# lpf5_target_db register map
Vendor: Texas Instruments
Peripheral module from a debugger description file (folder iva2_arp32).
Address unit: 16 bits
Registers are 32-bit, read-write, reset 0x0 unless marked. A register's access mark holds for its fields unless they carry their own. Offsets are as the file gives them; lines under a group give offsets from that group; [hi:lo] are bit positions; {n}, {i} and the like mark numbered series; 'fields as' and 'values as' point back to an identical list; <NAME> marks a mode.

## LPF5 — ipxact12_to_ccs_generated
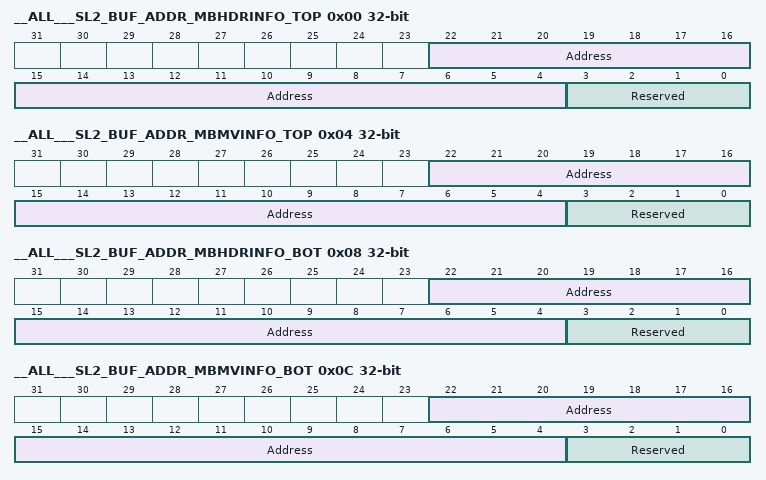
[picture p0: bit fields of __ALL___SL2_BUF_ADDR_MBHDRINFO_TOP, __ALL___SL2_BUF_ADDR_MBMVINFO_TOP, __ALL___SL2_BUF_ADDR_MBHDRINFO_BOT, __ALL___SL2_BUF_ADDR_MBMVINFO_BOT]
0x00 __ALL___SL2_BUF_ADDR_MBHDRINFO_TOP access per field — TOP MBHDRinfo Part1 SL2 Base Address ( Used for Encode Only; Kept for future potential need of reading Mbinfo in Decode)
  [22:4] Address rw
  [3:0] Reserved ro — Lower 4 bits of 128 bit aligned Sl2 Address.
0x04 __ALL___SL2_BUF_ADDR_MBMVINFO_TOP access per field — TOP MBinfo Part2 SL2 Base Address ( Used for Encoder Only; Kept for future potential need of reading Mbinfo in Decode)
  fields as __ALL___SL2_BUF_ADDR_MBHDRINFO_TOP
0x08 __ALL___SL2_BUF_ADDR_MBHDRINFO_BOT access per field — BOT MBinfo Part1 SL2 Base Address (Kept for future potential need of reading Mbinfo in Decode/Encode)
  fields as __ALL___SL2_BUF_ADDR_MBHDRINFO_TOP
0x0C __ALL___SL2_BUF_ADDR_MBMVINFO_BOT access per field — BOT MBinfo Part2 SL2 Base Address (Kept for future potential need of reading Mbinfo in Decode/Encode)
  fields as __ALL___SL2_BUF_ADDR_MBHDRINFO_TOP
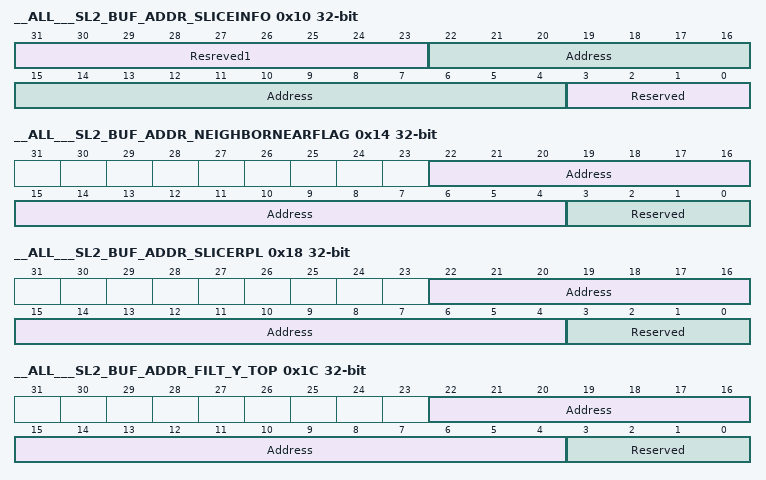
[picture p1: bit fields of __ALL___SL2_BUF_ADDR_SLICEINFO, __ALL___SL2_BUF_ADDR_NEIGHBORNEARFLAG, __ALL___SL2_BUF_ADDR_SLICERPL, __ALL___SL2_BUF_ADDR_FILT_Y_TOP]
0x10 __ALL___SL2_BUF_ADDR_SLICEINFO access per field — SliceInfo Buffer SL2 Base Address
  [31:23] Resreved1 ro
  [22:4] Address rw
  [3:0] Reserved ro — Lower 4 bits of 128 bit aligned Sl2 Address.
0x14 __ALL___SL2_BUF_ADDR_NEIGHBORNEARFLAG access per field — NeighborNear Flag ( BS=1) from ECD Buffer SL2 BA
  fields as __ALL___SL2_BUF_ADDR_MBHDRINFO_TOP
0x18 __ALL___SL2_BUF_ADDR_SLICERPL access per field — RPL Buffer SL2 BA ( Used only in case of Encoder to calculate refpic_id)
  fields as __ALL___SL2_BUF_ADDR_MBHDRINFO_TOP
0x1C __ALL___SL2_BUF_ADDR_FILT_Y_TOP access per field — Even lines of Filtered Luma Tiled-Buffer SL2 Base Addr
  fields as __ALL___SL2_BUF_ADDR_MBHDRINFO_TOP
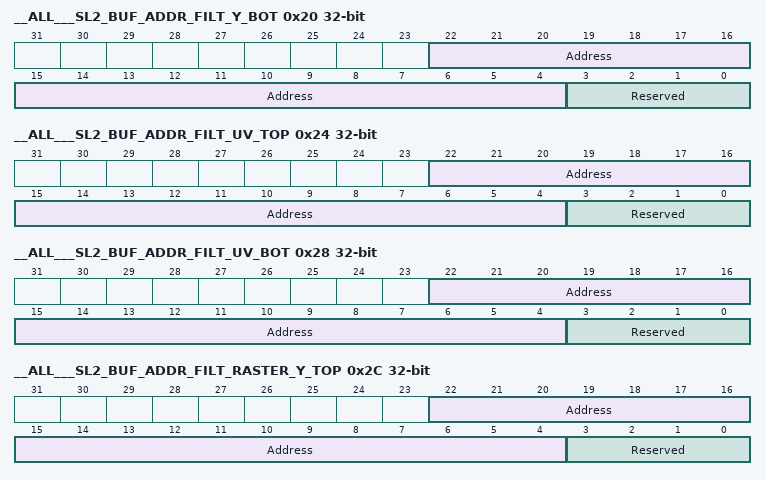
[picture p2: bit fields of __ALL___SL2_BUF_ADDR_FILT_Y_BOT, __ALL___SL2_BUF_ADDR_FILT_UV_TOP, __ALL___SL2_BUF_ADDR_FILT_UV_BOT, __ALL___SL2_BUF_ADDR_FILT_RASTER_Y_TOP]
0x20 __ALL___SL2_BUF_ADDR_FILT_Y_BOT access per field — Odd lines of Filtered Luma Tiled-Buffer SL2 Base Addr
  fields as __ALL___SL2_BUF_ADDR_MBHDRINFO_TOP
0x24 __ALL___SL2_BUF_ADDR_FILT_UV_TOP access per field — Even lines of Filtered Chroma(interleaved NV12) Tiled-Buffer SL2 Base Addr
  fields as __ALL___SL2_BUF_ADDR_MBHDRINFO_TOP
0x28 __ALL___SL2_BUF_ADDR_FILT_UV_BOT access per field — Odd lines of Filtered Chroma(interleaved NV12) Tiled-Buffer SL2 Base Addr
  fields as __ALL___SL2_BUF_ADDR_MBHDRINFO_TOP
0x2C __ALL___SL2_BUF_ADDR_FILT_RASTER_Y_TOP access per field — Even lines of Filtered Luma Raster-Buffer SL2 Base Addr
  fields as __ALL___SL2_BUF_ADDR_MBHDRINFO_TOP
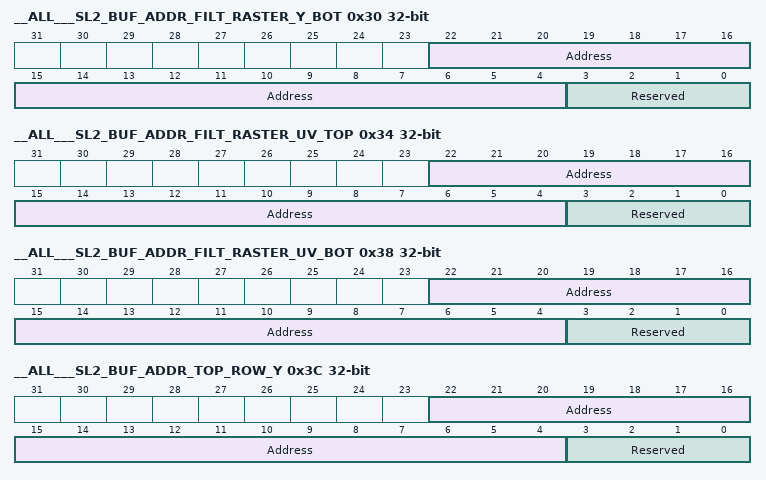
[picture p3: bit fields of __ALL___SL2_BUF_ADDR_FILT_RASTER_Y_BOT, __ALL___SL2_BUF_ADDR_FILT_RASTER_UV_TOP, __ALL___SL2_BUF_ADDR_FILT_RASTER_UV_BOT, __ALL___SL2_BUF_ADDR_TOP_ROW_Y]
0x30 __ALL___SL2_BUF_ADDR_FILT_RASTER_Y_BOT access per field — Odd lines of Filtered Luma Raster-Buffer SL2 Base Addr
  fields as __ALL___SL2_BUF_ADDR_MBHDRINFO_TOP
0x34 __ALL___SL2_BUF_ADDR_FILT_RASTER_UV_TOP access per field — Even lines of Filtered Chroma(interleaved NV12) Raster-Buffer SL2 Base Addr
  fields as __ALL___SL2_BUF_ADDR_MBHDRINFO_TOP
0x38 __ALL___SL2_BUF_ADDR_FILT_RASTER_UV_BOT access per field — Odd lines of Filtered Chroma(interleaved NV12) Raster-Buffer SL2 Base Addr
  fields as __ALL___SL2_BUF_ADDR_MBHDRINFO_TOP
0x3C __ALL___SL2_BUF_ADDR_TOP_ROW_Y access per field — TOP Row of Partially filtered Data Buffer SL2 Base Address. This is same as base adress for Luma. Cb and Cr base adresses are derived out of Luma base address by LPF5.
  fields as __ALL___SL2_BUF_ADDR_MBHDRINFO_TOP
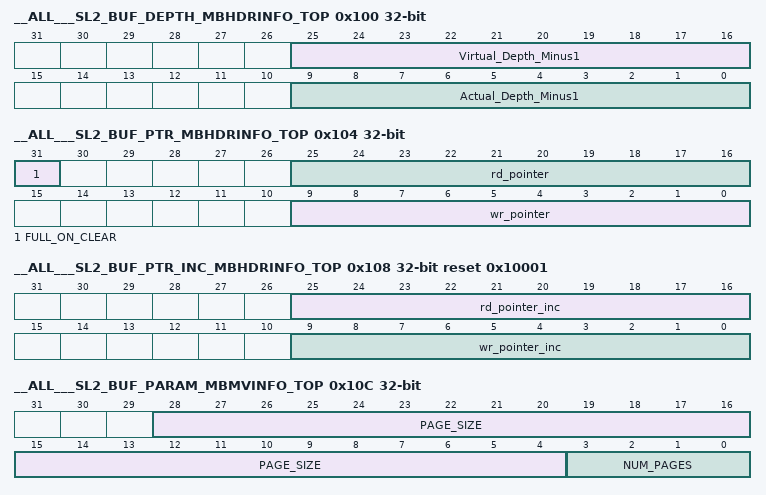
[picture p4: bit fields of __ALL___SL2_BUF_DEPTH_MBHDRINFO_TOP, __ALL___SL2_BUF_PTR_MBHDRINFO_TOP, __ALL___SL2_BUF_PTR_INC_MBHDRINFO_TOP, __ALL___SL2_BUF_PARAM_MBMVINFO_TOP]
0x100 __ALL___SL2_BUF_DEPTH_MBHDRINFO_TOP access per field — EVEN MBINFO Buffer depth configuration register
  [25:16] Virtual_Depth_Minus1 rw, [9:0] Actual_Depth_Minus1 rw
0x104 __ALL___SL2_BUF_PTR_MBHDRINFO_TOP access per field — EVEN MBINFO Buffer Pointer configuration register
  [31] FULL_ON_CLEAR rw
  [25:16] rd_pointer rw — Start value of Read pointer, initialized on BC_CLR. Range: 0 to Actual_buffer_depth_minus1
  [9:0] wr_pointer rw — Start value of Write pointer, initialized on BC_CLR. Range: 0 to Actual_buffer_depth_minus1
0x108 __ALL___SL2_BUF_PTR_INC_MBHDRINFO_TOP access per field reset 0x10001 — Configures the increment offset for buffer pointers of EVENMBInfo
  [25:16] rd_pointer_inc rw — Increment value for read pointer on rd_core_busy deassertion. Range: 0 to Actual_buffer_depth_minus1
  [9:0] wr_pointer_inc rw — Increment value for write pointer on wr_core_busy deassertion. Range: 0 to Actual_buffer_depth_minus1
0x10C __ALL___SL2_BUF_PARAM_MBMVINFO_TOP access per field — MBMVinfo Buffer parameters
  [28:4] PAGE_SIZE rw — Page Size of MBMV info in terms of Byte
  [3:0] NUM_PAGES rw — Number of MVinfo Pages
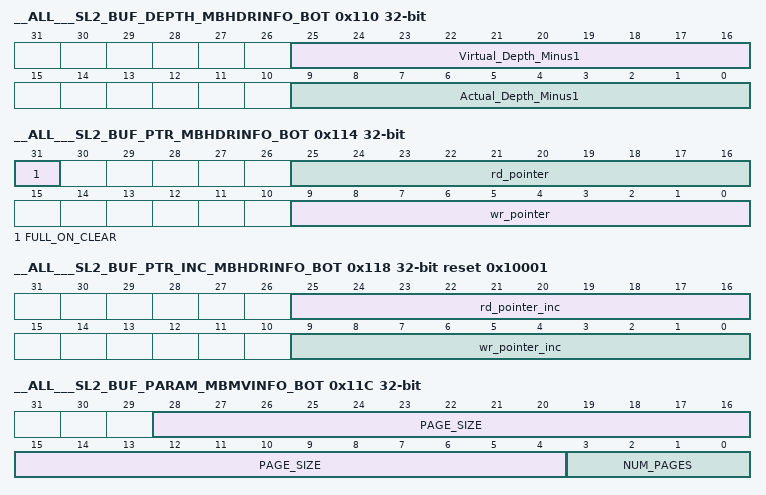
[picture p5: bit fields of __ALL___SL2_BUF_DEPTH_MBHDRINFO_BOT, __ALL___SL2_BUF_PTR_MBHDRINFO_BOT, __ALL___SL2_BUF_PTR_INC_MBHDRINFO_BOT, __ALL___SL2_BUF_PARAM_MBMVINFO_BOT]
0x110 __ALL___SL2_BUF_DEPTH_MBHDRINFO_BOT access per field — ODD MBINFO Buffer depth configuration register
  [25:16] Virtual_Depth_Minus1 rw, [9:0] Actual_Depth_Minus1 rw
0x114 __ALL___SL2_BUF_PTR_MBHDRINFO_BOT access per field — ODD MBINFO Buffer Pointer configuration register
  fields as __ALL___SL2_BUF_PTR_MBHDRINFO_TOP
0x118 __ALL___SL2_BUF_PTR_INC_MBHDRINFO_BOT access per field reset 0x10001 — Configures the increment offset for buffer pointers of ODD MBInfo
  fields as __ALL___SL2_BUF_PTR_INC_MBHDRINFO_TOP
0x11C __ALL___SL2_BUF_PARAM_MBMVINFO_BOT access per field — MBMVinfo Buffer parameters
  fields as __ALL___SL2_BUF_PARAM_MBMVINFO_TOP
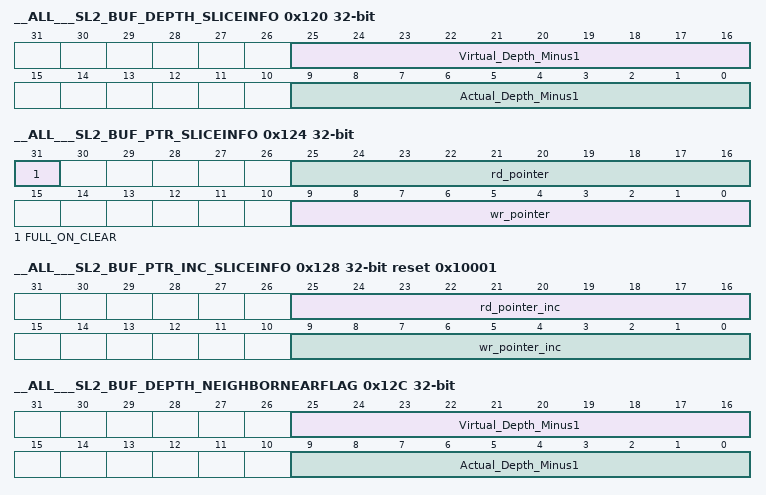
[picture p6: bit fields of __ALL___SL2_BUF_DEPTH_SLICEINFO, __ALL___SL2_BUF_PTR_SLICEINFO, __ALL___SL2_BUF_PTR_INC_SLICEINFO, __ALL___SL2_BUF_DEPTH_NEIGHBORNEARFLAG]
0x120 __ALL___SL2_BUF_DEPTH_SLICEINFO access per field — SliceInfo Buffer depth configuration register
  [25:16] Virtual_Depth_Minus1 rw, [9:0] Actual_Depth_Minus1 rw
0x124 __ALL___SL2_BUF_PTR_SLICEINFO access per field — SliceInfo Buffer Pointer configuration register
  fields as __ALL___SL2_BUF_PTR_MBHDRINFO_TOP
0x128 __ALL___SL2_BUF_PTR_INC_SLICEINFO access per field reset 0x10001 — Configures the increment offset for buffer pointers of SliceInfo
  fields as __ALL___SL2_BUF_PTR_INC_MBHDRINFO_TOP
0x12C __ALL___SL2_BUF_DEPTH_NEIGHBORNEARFLAG access per field — NearFlag Buffer depth configuration register
  [25:16] Virtual_Depth_Minus1 rw, [9:0] Actual_Depth_Minus1 rw
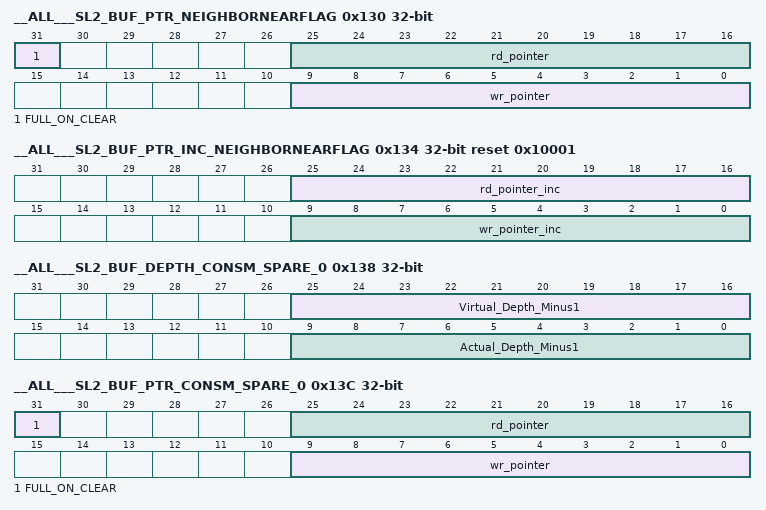
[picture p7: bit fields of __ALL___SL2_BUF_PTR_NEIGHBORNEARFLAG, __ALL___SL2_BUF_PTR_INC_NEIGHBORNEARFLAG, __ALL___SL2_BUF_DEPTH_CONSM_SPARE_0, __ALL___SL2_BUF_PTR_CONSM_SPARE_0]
0x130 __ALL___SL2_BUF_PTR_NEIGHBORNEARFLAG access per field — NeighborNear Flag Buffer Pointer configuration register
  fields as __ALL___SL2_BUF_PTR_MBHDRINFO_TOP
0x134 __ALL___SL2_BUF_PTR_INC_NEIGHBORNEARFLAG access per field reset 0x10001 — Configures the increment offset for buffer pointers of NeighborNear Flag
  fields as __ALL___SL2_BUF_PTR_INC_MBHDRINFO_TOP
0x138 __ALL___SL2_BUF_DEPTH_CONSM_SPARE_0 access per field — CONSM_SPARE_0 Buffer depth configuration register
  [25:16] Virtual_Depth_Minus1 rw, [9:0] Actual_Depth_Minus1 rw
0x13C __ALL___SL2_BUF_PTR_CONSM_SPARE_0 access per field — consumer spare 0 Buffer Pointer configuration register
  fields as __ALL___SL2_BUF_PTR_MBHDRINFO_TOP
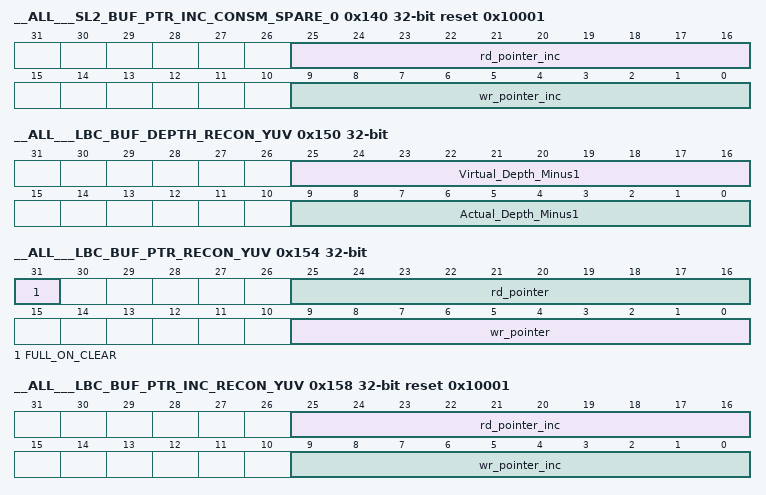
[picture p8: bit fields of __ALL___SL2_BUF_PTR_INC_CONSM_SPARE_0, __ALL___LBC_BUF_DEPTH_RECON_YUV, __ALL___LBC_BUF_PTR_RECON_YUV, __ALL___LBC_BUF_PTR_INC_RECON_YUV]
0x140 __ALL___SL2_BUF_PTR_INC_CONSM_SPARE_0 access per field reset 0x10001 — Configures the increment offset for buffer pointers of consumer spare 0 buffer
  fields as __ALL___SL2_BUF_PTR_INC_MBHDRINFO_TOP
0x150 __ALL___LBC_BUF_DEPTH_RECON_YUV access per field — CALC RECON Buffer depth configuration register
  [25:16] Virtual_Depth_Minus1 rw, [9:0] Actual_Depth_Minus1 rw
0x154 __ALL___LBC_BUF_PTR_RECON_YUV access per field — CALC Recon Buffer Pointer configuration register
  fields as __ALL___SL2_BUF_PTR_MBHDRINFO_TOP
0x158 __ALL___LBC_BUF_PTR_INC_RECON_YUV access per field reset 0x10001 — Configures the increment offset for buffer pointers of CALC DFIFO
  fields as __ALL___SL2_BUF_PTR_INC_MBHDRINFO_TOP
0x160 __ALL___LBC_BUF_BUFFER_ENTRY_SIZE access per field — Number of words in each BUFFER_ENTRY
  [5:0] BUFFER_ENTRY_SIZE_MINUS1 rw — Number of words in each BUFFER_ENTRY = BUFFER_ENTRY_SIZE_MINUS1+1 (4:2:2 --> 1024 Byte / MB of RECON_YUV otherwise 512Byte / MB)
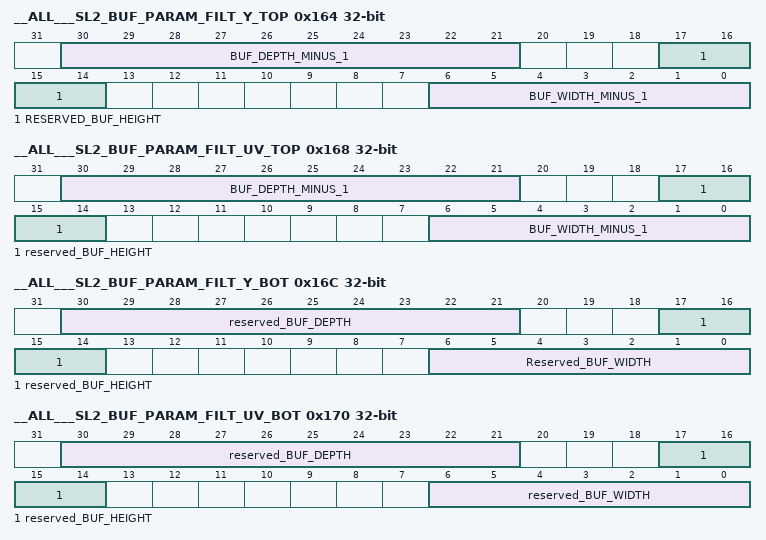
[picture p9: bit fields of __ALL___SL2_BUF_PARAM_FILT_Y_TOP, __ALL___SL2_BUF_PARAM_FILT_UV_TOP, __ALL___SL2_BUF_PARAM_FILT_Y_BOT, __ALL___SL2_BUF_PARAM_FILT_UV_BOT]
0x164 __ALL___SL2_BUF_PARAM_FILT_Y_TOP access per field — Even lines of Filterd Luma Tiled Buffer parameters
  [30:21] BUF_DEPTH_MINUS_1 rw — Number of Filter Buffer as interface between LPF and vDMA. 2 = Ping-pong Filter Buffers ( 2 set of filter buffers) 3 = 3 set of Filter Buffers. 16=16 set of Filter Buffers
  [17:14] RESERVED_BUF_HEIGHT ro — Filter Buffer Height ( Max 20 for H.264) reserved(read 0)
  [6:0] BUF_WIDTH_MINUS_1 rw — Width of Filter-Buffer in terms of 16byte ( Supported N-MB flow is for 1,2,4,8,16 MB )
0x168 __ALL___SL2_BUF_PARAM_FILT_UV_TOP access per field — Even lines of Filterd Chroma Tiled Buffer parameters
  [30:21] BUF_DEPTH_MINUS_1 rw — Number of Filter Buffer as interface between LPF and vDMA. 2 = Ping-pong Filter Buffers ( 2 set of filter buffers) 3 = 3 set of Filter Buffers. 16=16 set of Filter Buffers
  [17:14] reserved_BUF_HEIGHT ro — Filter Buffer Height ( Max 6 for H.264) reserved(read0)
  [6:0] BUF_WIDTH_MINUS_1 rw — Width of Buffer in terms of 16byte ( Supported N-MB flow is for 1,2,4,8,16 MB )
0x16C __ALL___SL2_BUF_PARAM_FILT_Y_BOT ro — Odd lines of Filterd Luma Tiled Buffer parameters
  [30:21] reserved_BUF_DEPTH — Number of Filter Buffer as interface between LPF and vDMA. 2 = Ping-pong Filter Buffers ( 2 set of filter buffers) 3 = 3 set of Filter Buffers. 16=16 set of Filter Buffers
  [17:14] reserved_BUF_HEIGHT — Filter Buffer Height ( Max 20 for H.264)
  [6:0] Reserved_BUF_WIDTH — Width of Buffer in terms of byte ( Supported N-MB flow is for 1,2,4,8,16 MB )
0x170 __ALL___SL2_BUF_PARAM_FILT_UV_BOT ro — Odd lines of Filterd Chroma Tiled Buffer parameters
  [30:21] reserved_BUF_DEPTH — Number of Filter Buffer as interface between LPF and vDMA. 2 = Ping-pong Filter Buffers ( 2 set of filter buffers) 3 = 3 set of Filter Buffers. 16=16 set of Filter Buffers
  [17:14] reserved_BUF_HEIGHT — Filter Buffer Height ( Max 6 for H.264)
  [6:0] reserved_BUF_WIDTH — Width of Buffer in terms of byte ( Supported N-MB flow is for 1,2,4,8,16 MB )
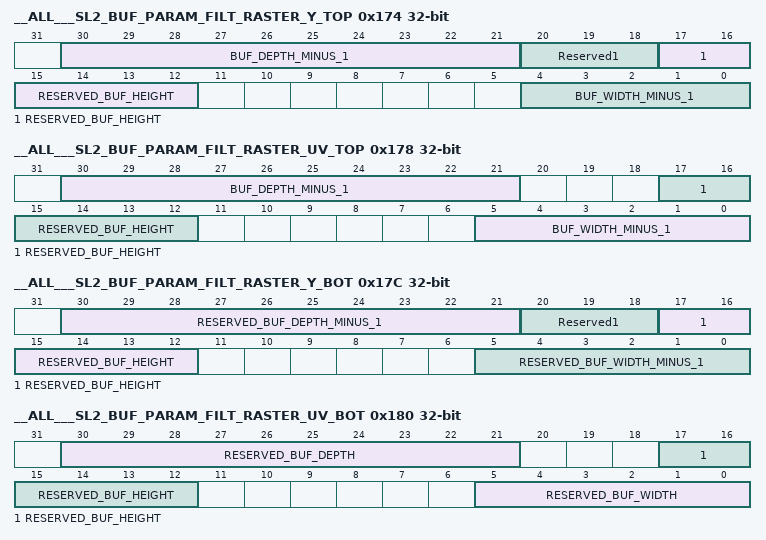
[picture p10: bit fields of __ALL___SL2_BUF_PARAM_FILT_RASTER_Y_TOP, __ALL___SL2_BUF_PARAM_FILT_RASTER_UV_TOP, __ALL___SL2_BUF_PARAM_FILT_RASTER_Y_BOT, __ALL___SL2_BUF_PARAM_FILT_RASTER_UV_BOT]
0x174 __ALL___SL2_BUF_PARAM_FILT_RASTER_Y_TOP access per field — Even lines of Filterd Luma Ratsre Buffer parameters
  [30:21] BUF_DEPTH_MINUS_1 rw — Number of Filter-Buffers as interface between LPF and vDMA. 2 = Ping-pong Filter Buffers ( 2 set of filter buffers) 3 = 3 set of Filter Buffers. 16=16 set of Filter Buffers
  [20:18] Reserved1 ro — 64x64 support
  [17:12] RESERVED_BUF_HEIGHT ro — Height of Filter-Buffer ( Max 20 for H.264 Non-MBAFF; 40 for MBAFF) Reserved (Read 0)
  [4:0] BUF_WIDTH_MINUS_1 rw — Width of 1 entry of Filter-Buffer in terms of 16byte (Supported N-MB flow is for 1,2,4,8,16 MB)
0x178 __ALL___SL2_BUF_PARAM_FILT_RASTER_UV_TOP access per field — Even lines of Filterd Chroma(interleaved,NV12) Raster Buffer parameters
  [30:21] BUF_DEPTH_MINUS_1 rw — Number of Filter Buffer as interface between LPF and vDMA. 2 = Ping-pong Filter Buffers ( 2 set of filter buffers) 3 = 3 set of Filter Buffers. 16=16 set of Filter Buffers
  [17:12] RESERVED_BUF_HEIGHT ro — Filter Buffer Height ( Max 12 for H.264) Reserved(read 0)
  [5:0] BUF_WIDTH_MINUS_1 rw — Width of Buffer in terms of 16byte ( Supported N-MB flow is for 1,2,4,8,16 MB )
0x17C __ALL___SL2_BUF_PARAM_FILT_RASTER_Y_BOT ro — Odd lines of Filterd Luma Ratsre Buffer parameters
  [30:21] RESERVED_BUF_DEPTH_MINUS_1 — Number of Filter-Buffers as interface between LPF and vDMA. 2 = Ping-pong Filter Buffers ( 2 set of filter buffers) 3 = 3 set of Filter Buffers. 16=16 set of Filter Buffers
  [20:18] Reserved1 — 64x64 support
  [17:12] RESERVED_BUF_HEIGHT — Height of Filter-Buffer ( Max 20 for H.264) Reserved (Read 0)
  [5:0] RESERVED_BUF_WIDTH_MINUS_1 — Width of 1 entry of Filter-Buffer in terms of 16byte ( Supported N-MB flow is for 1,2,4,8,16 MB )
0x180 __ALL___SL2_BUF_PARAM_FILT_RASTER_UV_BOT ro — Odd lines of Filterd Chroma(interleaved,NV12) Raster Buffer parameters
  [30:21] RESERVED_BUF_DEPTH — Number of Filter Buffer as interface between LPF and vDMA. 2 = Ping-pong Filter Buffers ( 2 set of filter buffers) 3 = 3 set of Filter Buffers. 16=16 set of Filter Buffers
  [17:12] RESERVED_BUF_HEIGHT — Filter Buffer Height ( Max 12 for H.264)
  [5:0] RESERVED_BUF_WIDTH — Width of Buffer in terms of 16byte ( Supported N-MB flow is for 1,2,4,8,16 MB )
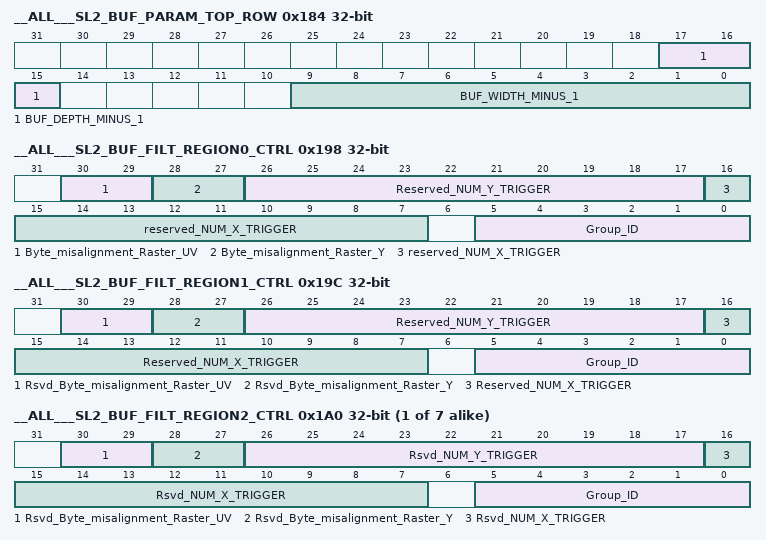
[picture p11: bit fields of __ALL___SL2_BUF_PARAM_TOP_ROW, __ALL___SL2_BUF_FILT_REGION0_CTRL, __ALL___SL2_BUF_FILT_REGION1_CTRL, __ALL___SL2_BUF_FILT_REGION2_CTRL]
0x184 __ALL___SL2_BUF_PARAM_TOP_ROW access per field — TOP ROW Pixels Buffer parameters
  [17:15] BUF_DEPTH_MINUS_1 rw — Configure it to 2 always whenver store into DDR is configured. Configure it to 0 always whenver store into DDR is NOT configured. Kept for future expansion.
  [9:0] BUF_WIDTH_MINUS_1 rw — Buffer Width in terms of 16Bytes. Worst case for 16K frame width with no store into DDR.
0x190 __ALL___SL2_BUF_PARAM_TOP_ROW_STORE_CTRL access per field — Control parameter for top-row buffer Store into DDR
  [5:0] Group_ID rw — Group ID used to trigger vDMA transfer for Store
0x194 __ALL___SL2_BUF_PARAM_TOP_ROW_LOAD_CTRL access per field — Control parameter for top-row buffer load from DDR
  [5:0] Group_ID rw — Group ID used to trigger vDMA transfer for Load
0x198 __ALL___SL2_BUF_FILT_REGION0_CTRL access per field — Region0 Control Parameters
  [30:29] Byte_misalignment_Raster_UV rw — Multiple of 4Byte misalignent in writing Luma data into Filter Buffer for Raster OUT
  [28:27] Byte_misalignment_Raster_Y rw — Multiple of 4Byte misalignent in writing Luma data into Filter Buffer for Raster OUT
  [26:17] Reserved_NUM_Y_TRIGGER ro — Number of Y Trigger used to trigger vDMA transfer for Region#0.
  [16:7] reserved_NUM_X_TRIGGER ro — Number of X Trigger used to trigger vDMA transfer for Region#0.
  [5:0] Group_ID rw — Group ID used to trigger vDMA transfer for Region#0.
0x19C __ALL___SL2_BUF_FILT_REGION1_CTRL access per field — Region1 Control Parameters
  [30:29] Rsvd_Byte_misalignment_Raster_UV ro — Multiple of 4Byte misalignent in writing Luma data into Filter Buffer for Raster OUT
  [28:27] Rsvd_Byte_misalignment_Raster_Y ro — Multiple of 4Byte misalignent in writing Luma data into Filter Buffer for Raster OUT
  [26:17] Reserved_NUM_Y_TRIGGER ro — Number of Y Trigger used to trigger vDMA transfer for Region#1.
  [16:7] Reserved_NUM_X_TRIGGER ro — Number of X Trigger used to trigger vDMA transfer for Region#1.
  [5:0] Group_ID rw — Group ID used to trigger vDMA transfer for Region#1.
{0x198+4i} __ALL___SL2_BUF_FILT_REGION{i}_CTRL access per field (i=2..8) — Region{i} Control Parameters
  [30:29] Rsvd_Byte_misalignment_Raster_UV ro — Multiple of 4Byte misalignent in writing Luma data into Filter Buffer for Raster OUT
  [28:27] Rsvd_Byte_misalignment_Raster_Y ro — Multiple of 4Byte misalignent in writing Luma data into Filter Buffer for Raster OUT
  [26:17] Rsvd_NUM_Y_TRIGGER ro — Number of Y Trigger used to trigger vDMA transfer for Region#{i}.
  [16:7] Rsvd_NUM_X_TRIGGER ro — Number of X Trigger used to trigger vDMA transfer for Region#{i}.
  [5:0] Group_ID rw — Group ID used to trigger vDMA transfer for Region#{i}.
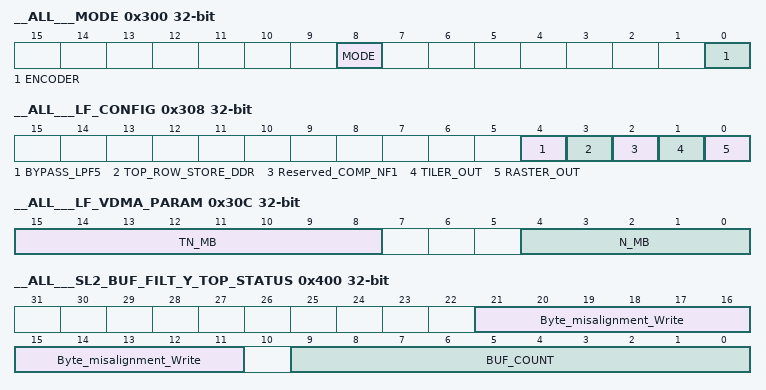
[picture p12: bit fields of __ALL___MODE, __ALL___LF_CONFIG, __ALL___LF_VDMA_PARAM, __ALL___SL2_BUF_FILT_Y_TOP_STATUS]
0x300 __ALL___MODE access per field — LPF Mode register
  [8] MODE rw — 0=>H.241, 1=>Normal
  [0] ENCODER rw — 0=>Decoder, 1=>Encoder
0x304 __ALL___CODEC_TYPE access per field — LPF codec type register
  [3:0] CODEC_TYPE rw — 0=>H.264, 1=>SVC, 2=> reserved
0x308 __ALL___LF_CONFIG access per field — Configuraiton parameter for LPF operation
  [4] BYPASS_LPF5 rw — Bypass LPF5 operations, except loading pixels from REOCN_YUV and storing into SL2. No need to create Left column and create top row or buffer inside SL2. use single descriptor to transfer full RECON_YUV buffer into SL2. ALways use region#4 descriptors.
  [3] TOP_ROW_STORE_DDR rw — TOP row store/load into/from DDR
  [2] Reserved_COMP_NF1 rw — Compute NeighborNear Flag inside ECD5 or LPF5. SW MUST Write '0' into this bit.
  [1] TILER_OUT rw — TILER OUT filter data
  [0] RASTER_OUT rw — RASTER OUT filter data
0x30C __ALL___LF_VDMA_PARAM access per field
  [15:8] TN_MB rw — Value of TN to be used for storing/loading TN_MB partially filtered top-row data through VDMA. Legal Values of TN=16,32,64,128
  [4:0] N_MB rw — Value of N to be used for transferring N-MB filtered data through VDMA. Legal Values of N=1,2,4,8,16 N_MB parameter is fixed for complete frame. It can't change during frame/picture processing.
0x400 __ALL___SL2_BUF_FILT_Y_TOP_STATUS access per field — Buffer Status of Even lines of Luma as Tiled
  [21:11] Byte_misalignment_Write rw
  [9:0] BUF_COUNT rw — Buffer Count within Circular Buffer
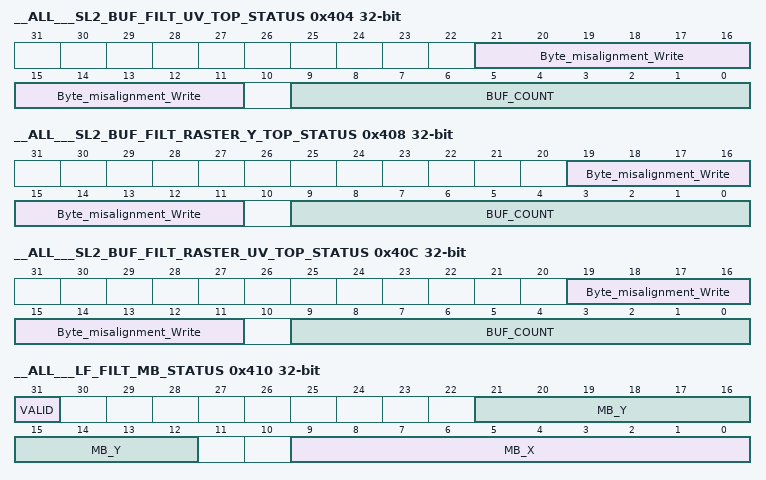
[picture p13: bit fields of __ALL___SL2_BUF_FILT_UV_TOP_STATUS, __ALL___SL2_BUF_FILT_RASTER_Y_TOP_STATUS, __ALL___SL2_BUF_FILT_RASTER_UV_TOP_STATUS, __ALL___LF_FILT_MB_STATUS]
0x404 __ALL___SL2_BUF_FILT_UV_TOP_STATUS access per field — Buffer Status of Even lines of Chroma as Tiled
  [21:11] Byte_misalignment_Write rw — Byte Misalignment from Filter Buffer for current N-MB container.
  [9:0] BUF_COUNT rw — Buffer Count within Circular Buffer
0x408 __ALL___SL2_BUF_FILT_RASTER_Y_TOP_STATUS access per field — Buffer Status of Even lines of Luma as Raster
  [19:11] Byte_misalignment_Write rw — BYte migalignment from Current Filter Buffer start
  [9:0] BUF_COUNT rw — Buffer Count within Filter-Buffer
0x40C __ALL___SL2_BUF_FILT_RASTER_UV_TOP_STATUS access per field — Buffer Status of Even lines of Chroma as Raster
  [19:11] Byte_misalignment_Write rw
  [9:0] BUF_COUNT rw — Buffer Count within Circular Buffer
0x410 __ALL___LF_FILT_MB_STATUS access per field — MB number which is fully filtered into SL2
  [31] VALID rw
  [21:12] MB_Y rw — row number of MB filtered and stored into SL2
  [9:0] MB_X rw — column number of MB filtered and stored into SL2
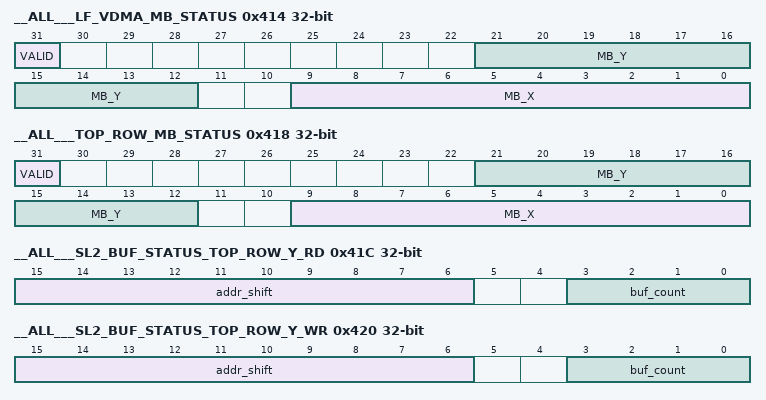
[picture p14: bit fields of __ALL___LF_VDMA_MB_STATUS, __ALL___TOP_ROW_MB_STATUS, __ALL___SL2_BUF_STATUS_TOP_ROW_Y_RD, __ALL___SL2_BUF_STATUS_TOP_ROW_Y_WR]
0x414 __ALL___LF_VDMA_MB_STATUS access per field — MB number which is fully transferrred into DDR
  [31] VALID rw
  [21:12] MB_Y rw — Row number of MB transferred into DDR
  [9:0] MB_X rw — column number of MB transferred into DDR
0x418 __ALL___TOP_ROW_MB_STATUS access per field — MB number whose partially filtered bottom pixels are fully transferred into DDR. This register is also used to track MB number which is fully loaded from DDR. Hence in bottom row of Frame, this register is used to extract loaded MB position, as no store takes place in bottom of frame
  [31] VALID rw
  [21:12] MB_Y rw — row number of MB
  [9:0] MB_X rw — column number of MB. If MB_X >= frame_width in MB, which means end of row has reached.
0x41C __ALL___SL2_BUF_STATUS_TOP_ROW_Y_RD access per field — Operational Read parameters of TOP ROW pixels for Luma
  [15:6] addr_shift rw — address shift from current Buffer for reading next top row 4x4 block
  [3:0] buf_count rw — Buffer count of top-row buffer for Luma Loading
0x420 __ALL___SL2_BUF_STATUS_TOP_ROW_Y_WR access per field — Operational Write parameters of TOP ROW pixels for Luma
  [15:6] addr_shift rw — address shift from current Buffer for storing next top row 4x4 block
  [3:0] buf_count rw — Buffer count of top-row buffer for Luma Storing
0x424 __ALL___SL2_BUF_STATUS_TOP_ROW_U_RD access per field — Operational Read parameters of TOP ROW pixels for Cb
  [15:6] addr_shift rw — address shift from current Buffer for reading next top row 4x4 block
  [3:0] buf_count rw — Buffer count of top-row buffer for Cb Loading
0x428 __ALL___SL2_BUF_STATUS_TOP_ROW_U_WR access per field — Operational Write parameters of TOP ROW pixels for Cb
  [15:6] addr_shift rw — address shift from current Buffer for storing next top row 4x4 block
  [3:0] buf_count rw — Buffer count of top-row buffer for Cb Storing
0x42C __ALL___SL2_BUF_STATUS_TOP_ROW_V_RD access per field — Operational Read parameters of TOP ROW pixels for Cr
  [15:6] addr_shift rw — address shift from current Buffer for reading next top row 4x4 block
  [3:0] buf_count rw — Buffer count of top-row buffer for Cr Loading
0x430 __ALL___SL2_BUF_STATUS_TOP_ROW_V_WR access per field — Operational Write parameters of TOP ROW pixels for Cr
  [15:6] addr_shift rw — address shift from current Buffer for storing next top row 4x4 block
  [3:0] buf_count rw — Buffer count of top-row buffer for Cr Storing
0x434 __ALL___TOP_ROW_STORE_STATUS access per field — Buffer status info for storing into DDR
  [3:0] BUF_COUNT rw — Buffer Count within Circular Buffer
0x438 __ALL___TOP_ROW_LOAD_STATUS access per field — Buffer status info for Loading from DDR
  [3:0] BUF_COUNT rw — Buffer Count within Circular Buffer
0x43C __ALL___SL2_BUF_PTR_VDMA_TRIGGER access per field — VDMA TRIGGer Buffer Pointer configuration register
  [31] FULL_ON_CLEAR rw
  [25:16] rd_pointer rw — Start value of Read pointer, initialized on BC_CLR. Range: 0 to frame_width_in_MB_Minus_1
  [9:0] wr_pointer rw — Start value of Write pointer, initialized on BC_CLR. Range: 0 to frame_width_in_MB_Minus_1
0x440 __ALL___LF_LEFT_TOP_LF_PARAM access per field — Left Top MB Parameters
  [22:16] QP_CR rw
  [15:9] QP_CB rw
  [8:2] QP_Y rw — QP(Luma)
  [1] Frame_MB rw — Frame/Field MB for MBAFF.
  [0] INTRA rw
0x444 __ALL___LF_LEFT_BOT_LF_PARAM access per field — Left Bot MB Parameters
  fields as __ALL___LF_LEFT_TOP_LF_PARAM
0x448 __ALL___LF_LEFT_CBP access per field — Calculated CBP for Left MB/MB-pair ( Saving relevent CBP fileds from current MB/MB-pair for Left MB))
  [19] LEFT_BOT_MB_NEIGHBOR_CBP_3 rw — Neighbor Blockid[15] (MB-pair)
  [18] LEFT_BOT_MB_NEIGHBOR_CBP_2 rw — Neighbor Blockid[13] (MB-Pair)
  [17] LEFT_BOT_MB_NEIGHBOR_CBP_1 rw — Neighbor Blockid[7] (MB-pair)
  [16] LEFT_BOT_MB_NEIGHBOR_CBP_0 rw — Neighbor Blockid[5] of LEFT BOT (MB-pair )
  [3] LEFT_TOP_MB_NEIGHBOR_CBP_3 rw — Neighbor Blockid[15]
  [2] LEFT_TOP_MB_NEIGHBOR_CBP_2 rw — Neighbor Blockid[13]
  [1] LEFT_TOP_MB_NEIGHBOR_CBP_1 rw — Neighbor Blockid[7]
  [0] LEFT_TOP_MB_NEIGHBOR_CBP_0 rw — Neighbor Blockid[5]
0x44C __ALL___LF_CURMB_PROPERTY access per field — Operational property of Current MB/MB-pair.
  [3] MBAFF_TOP_MB rw — indicates top/bot of MBAFF MB-pair.
  [2] FRAME_TOP_ROW rw — indicates whether current MB belongs to top row of Frame.
  [0] SLICE_VALID rw
0x600 __ALL___PID ro reset 0x40000000 — IP Revision Identifier This allows a PID showing X.Y.R in silicon to relate the RTL release with a (close-to-correct) spec version X.Y.S.
  [31:30] scheme — Used to distinguish between old Scheme and current. Spare bit to encode future schemes. Highlander 0.8 value: 0b01
  [27:16] func — Function indicates a software compatible module family. If there is no level of software compatibility a new Func number (and hence PID) should be assigned.
  [15:11] rtl — RTL Version. R as described in PDR with additional clarifications/definitions below. Must be easily ECO-able or controlled during fabrication. Ideally through a top level metal mask or e-fuse. This number is maintained/owned by IP design owner. RTL follows a numbering such as X.Y.R.Z which are explained in this table. R changes ONLY when: (1) PDS uploads occur which may have been due to spec changes (2) Bug fixes occur (3) Resets to '0' when X or Y changes. Design team has an internal 'Z' (customer invisible) number which increments on every drop that happens due to DV and RTL updates. Z resets to 0 when R increments.
  [10:8] major — Major Revision. X as described in PDR with additional clarifications/definitions below. This number is owned/maintained by IP specification owner. X changes ONLY when: (1) There is a major feature addition. An example would be adding Master Mode to Utopia Level2. The Func field (or Class/Type in old PID format) will remain the same. X does NOT change due to: (1) Bug fixes (2) Change in feature parameters.
  [7:6] custom — Indicates a special version for a particular device. Consequence of use may avoid use of standard Chip Support Library (CSL) / Drivers. 0 if non-custom.
  [5:0] minor — Minor Revision. Y as described in PDR with additional clarifications/definitions below. This number is owned/maintained by IP specification owner. Y changes ONLY when: (1) Features are scaled (up or down). Flexibility exists in that this feature scalability may either be represented in the Y change or a specific register in the IP that indicates which features are exactly available. (2) When feature creeps from Is-Not list to Is list. But this may not be the case once it sees silicon; in which case X will change. Y does NOT change due to: (1) Bug fixes (2) Typos or clarifications (3) major functional/feature change/addition/deletion. Instead these changes may be reflected via R, S, X as applicable. Spec owner maintains a customer-invisible number 'S' which changes due to: (1) Typos/clarifications (2) Bug documentation. Note that this bug is not due to a spec change but due to implementation. Nevertheless, the spec tracks the IP bugs. An RTL release (say for silicon PG1.1) that occurs due to bug fix should document the corresponding spec number (X.Y.S) in its release notes.
0x604 __ALL___SYSCONFIG access per field reset 0x8 — Clock management configuration
  [3:2] idlemode rw — Configuration of the local target state management mode. By definition, target can handle read/write transaction as long as it is out of IDLE state.
  [1] AUTOCLOCKGATING_OFF rw — By Default LPF internal sub-modules clocks would be gated based on their activity, for power saving. IF user wishes to run LPF with all its internal clocks are free-running wrt input clock of LPF this bit can be used. 0 = Auto clock gating ON 1 = Auto clock gating OFF
  [0] softreset rw — Software reset. Read 0: Software reset done, no pending action Write 0: No action Write 1: Initiate software reset Read 1: Software reset ongoing Note that great care should be taken when SW user fires SW reset. SW must ensure that all interacting thread with IVAHD level (SL2,AUx-SL2,vDMA groyup one etc ) is idle before issuing SW reset. Otherwise behavior is unpredictable.
0x60C __ALL___IRQ_STATUS_RAW_0 access per field — Per-event raw interrupt status vector, line #0. Raw status is set even if event is not enabled.Write 1 to set the (raw) status, mostly for debug. Write 0: No action Read 0: No event pending Read 1: Event pending Write 1: Set event (debug)
  [8] TOP_ROW_TRANSFER_DONE rw — LPF5 vdma trigger for top-rowbuffer load/store is serviced (group done received).
  [7] FILT_TRANSFER_DONE rw — LPF5 vdma trigger for filtered data transfer is serviced (group done received).
  [6] REWIND_ACK rw — LPF finished pending MB processing including all pending (same stage included) vDMA thread closed , after receiving rewind_pipeline.
  [5] TIMEOUT_ERROR rw — Timeout Error Detected as per LPF_** MMR
  [4] DATA_SYNC rw — settable raw status at DATA SYNC point.
  [3] PIPE_DOWN rw — settable raw status at End of PIPE processing (LPF filter is over and all related vDMA thread is closed)
  [2] END_OF_ROW rw — settable raw status at End of ROW processing ( LPF filtered data for current MB ROW is fully/partially available in SL2; vDMA transfer status NOT known)
  [1] END_OF_SLICE rw — settable raw status at End of Slice processing ( LPF filtered data for current Slice fully/partially available in SL2; vDMA transfer status NOT known)
  [0] END_OF_MB rw — settable raw status at End of MB processing ( LPF filtered data for current MB available in SL2; vDMA transfer status NOT known)
0x610 __ALL___IRQ_STATUS_0 access per field — Per-event "enabled" interrupt status vector, line #0. Enabled status isn't set unless event is enabled. Write 1 to clear the status after interrupt has been serviced (raw status gets cleared, i.e. even if not enabled). Write 0: No action Read 0: No Enabled event pending Read 1: Enabled Event pending Write 1: CLear raw event
  [8] TOP_ROW_TRANSFER_DONE rw — If enabled, LPF5 vdma trigger for top-rowbuffer load/store is serviced (group done received).
  [7] FILT_TRANSFER_DONE rw — If enabled, LPF5 vdma trigger for filtered data transfer is serviced (group done received).
  [6] REWIND_ACK rw — If enabled, LPF finished pending MB processing including all pending (same stage included) vDMA thread closed , after receiving rewind_pipeline.
  [5] TIMEOUT_ERROR rw — Timeout Error if enabled
  [4] DATA_SYNC rw — DATA SYNC point if enabled
  [3] PIPE_DOWN rw — End of PIPE processing if enabled (LPF filter is over and all related vDMA thread is closed)
  [2] END_OF_ROW rw — End of ROW processing if enabled ( LPF filtered data for current MB ROW is fully/partially available in SL2; vDMA transfer status NOT known)
  [1] END_OF_SLICE rw — End of Slice processing if enabled ( LPF filtered data for current Slice fully/partially available in SL2; vDMA transfer status NOT known)
  [0] END_OF_MB rw — settable status at End of MB processing ( LPF filtered data for current MB available in SL2; vDMA transfer status NOT known)
0x614 __ALL___IRQ_ENABLE_SET_0 access per field — Per-event interrupt enable bit vector, line #0. Write 1 to set (enable interrupt). Readout equal to corresponding _CLR register. Write 0: No action Read 0: Interrupt disabled (masked) Read 1: Interrupt enabled Write 1: Enable interrupt
  [8] TOP_ROW_TRANSFER_DONE rw — Enable for TOP_ROW_TRANSFER_DONE
  [7] FILT_TRANSFER_DONE rw — Enable for FILT_TRANSFER_DONE
  [6] REWIND_ACK rw — Enable for REWIND_ACK
  [5] TIMEOUT_ERROR rw — Enable for TIMEOUT_ERROR
  [4] DATA_SYNC rw — Enable for DATA_SYNC
  [3] PIPE_DOWN rw — Enable for PIPE_DOWN
  [2] END_OF_ROW rw — Enable for END_OF_ROW
  [1] END_OF_SLICE rw — Enable for END_OF_SLICE
  [0] END_OF_MB rw — enable for END_OF_MB
0x618 __ALL___IRQ_ENABLE_CLR_0 access per field — Per-event interrupt enable bit vector, line #0. Write 1 to clear (disable interrupt). Readout equal to corresponding _SET register. Write 0: No action Read 0: Interrupt disabled (masked) Read 1: Interrupt enabled Write 1: Disable interrupt
  fields as __ALL___IRQ_ENABLE_SET_0
0x61C __ALL___IRQ_BLOCKING_CFG_0 access per field — Interrupt blocking configuration for interrupt line - 0
  [8] TOP_ROW_TRANSFER_DONE rw — Blocking configuration for interrupt source_0 1: interrupt source is blocking type 0: interrupt source is non-blocking type. The configuration in this register only apply to enabled interrupt sources
  [7] FILT_TRANSFER_DONE rw — Blocking configuration for interrupt source_0 1: interrupt source is blocking type 0: interrupt source is non-blocking type. The configuration in this register only apply to enabled interrupt sources
  [6] REWIND_ACK rw — Blocking configuration for interrupt source_0 1: interrupt source is blocking type 0: interrupt source is non-blocking type. The configuration in this register only apply to enabled interrupt sources
  [5] TIMEOUT_ERROR rw — Blocking configuration for interrupt source_0 1: interrupt source is blocking type 0: interrupt source is non-blocking type. The configuration in this register only apply to enabled interrupt sources
  [4] DATA_SYNC rw — Blocking configuration for interrupt source_0 1: interrupt source is blocking type 0: interrupt source is non-blocking type. The configuration in this register only apply to enabled interrupt sources
  [3] PIPE_DOWN rw — Blocking configuration for interrupt source_0 1: interrupt source is blocking type 0: interrupt source is non-blocking type. The configuration in this register only apply to enabled interrupt sources
  [2] END_OF_ROW rw — Blocking configuration for interrupt source_0 1: interrupt source is blocking type 0: interrupt source is non-blocking type. The configuration in this register only apply to enabled interrupt sources
  [1] END_OF_SLICE rw — Blocking configuration for interrupt source_0 1: interrupt source is blocking type 0: interrupt source is non-blocking type. The configuration in this register only apply to enabled interrupt sources
  [0] END_OF_MB rw — Blocking configuration for interrupt source_0 1: interrupt source is blocking type 0: interrupt source is non-blocking type. The configuration in this register only apply to enabled interrupt sources
0x640 __ALL___LF_ENABLE access per field — LPF5 Enable Register
  [0] ENABLE rw
0x644 __ALL___PROGRAM_AUTO_LOAD access per field — Enable and SL2 location of the Auto Load MMR Image
  [31] AUTO_PROGRAM_LOAD_EN rw — Auto Load Enabled 1 => Program Auto Load Enabled
  [22:4] AUTO_PROGRAM_ADDR rw — Program Auto Load SL2 Base Address
0x64C __ALL___LF_DATA_SYNC access per field — Number of rows to generate interrupt after finishing filter and complete transfer of filtered data of N Rows in DDR( Taske care of vDMA thread)
  [8:0] NUM_ROWS rw — Starting with Row No = 0 till Row No= 511(for 8K); Interrupt would be generated after filterring and completing vDMA transfer of all MB of number of rows configured here from previous interrupt generation. i.e. interrupt would be generated after row_number NUM_ROWS, 2*NUM_ROWS, 3*NUM_ROWS and continues..
0x650 __ALL___LF_BC_CLR access per field — SYNCBOX5 register Initializes the BC pointers to the configured values (as configured in the BC_PTR MMR). Single BC_CLR register in HWA with a CLEAR bit per buffer. CLEAR bits should exist for both output & input buffers. BC_CLR should be set only when the BC is in IDLE State and all the other BC registers are programmed to avoid the undefined behaviour. Software needs to ensure that BC_CLR write is non-posted.
  [6] LF_VDMA_TRIGGER wo — Internal SL2BC for vDMA trigger management.
  [5] LBC_BUF_RECON_YUV_CLEAR wo
  [4] SL2_BUF_CONSM_SPARE_0_CLEAR wo
  [3] SL2_BUF_NEIGHBORNEARFLAG_CLEAR wo
  [2] SL2_BUF_SLICEINFO_CLEAR wo
  [1] SL2_BUF_MBHDRINFO_BOT_CLEAR wo
  [0] SL2_BUF_MBHDRINFO_TOP_CLEAR wo
0x654 __ALL___LF_CORE_TIMEOUT access per field reset 0xFA0 — Timeout Error detection
  [12:1] CYCLE_COUNT rw — Cycle count for Time out detection.
  [0] EN rw — Enabling timeout feature
0x658 __ALL___LF_VDMA_TIMEOUT access per field reset 0xFA0 — Timeout Error detection
  fields as __ALL___LF_CORE_TIMEOUT
0x65C __ALL___BC_ENABLE access per field — Enable MMR for BCs in LPF5. If register bit is 0, the corresponding BC's ready is not looked for thread to proceed its execution. '1' = Enable BC Ready '0' = Disable BC ready
  [9] BC_EN_VDMA_TOP_ROW_LOAD_TRIGGER rw — Enabling BC Readys
  [8] BC_EN_VDMA_TOP_ROW_STORE_TRIGGER rw — Enabling BC Readys
  [7] BC_EN_VDMA_FILT_TRIGGER rw — Enabling BC Readys
  [6] BC_EN_RECON_YUV rw — Enabling BC Readys
  [5] BC_EN_PROD_SPARE_0 rw — Enabling BC Readys
  [4] BC_EN_CONSM_SPARE_0 rw — Enabling BC Readys
  [3] BC_EN_NEIGHBORNEARFLAG rw — Enabling BC Readys
  [2] BC_EN_SLICEINFO rw — Enabling BC Readys
  [1] BC_EN_MBHDRINFO_BOT rw — Enabling BC Readys
  [0] BC_EN_MBHDRINFO_TOP rw — Enabling BC Readys
0x660 __ALL___LF_BC_GLUE_CLR access per field — Always write '0' into this register.
  [9] LF_VDMA_TOP_ROW_LOAD_GLUE_CLR rw, [8] LF_VDMA_TOP_ROW_STORE_GLUE_CLR rw, [7] LF_VDMA_FILT_TRIGGER_GLUE_CLR wo, [6] LBC_BUF_RECON_YUV_GLUE_CLR wo, [5] SL2_BUF_PROD_SPARE_0_GLUE_CLR wo, [4] SL2_BUF_CONSM_SPARE_0_GLUE_CLR wo, [3] SL2_BUF_NEIGHBORNEARFLAG_GLUE_CLR wo, [2] SL2_BUF_SLICEINFO_GLUE_CLR wo, [1] SL2_BUF_MBHDRINFO_BOT_GLUE_CLR wo, [0] SL2_BUF_MBHDRINFO_TOP_GLUE_CLR wo
0x664 __ALL___BC_IDLE access per field — Disables the bc_ready generation. Bc_pointer is untouched
  [8] LF_VDMA_TOP_ROW_LOAD_IDLE wo — Internal custom fifo to handle top-row trigger generation for load. Don't use this bit.
  [7] LF_VDMA_TOP_ROW_STORE_IDLE wo — Internal custom fifo to handle top-row trigger generation for store. Load Buffer interface is handled through this bit only. Back up bit for future.
  [6] LF_VDMA_TRIGGER_IDLE wo — Internal SL2BC for vDMA trigger management.
  [5] LBC_BUF_RECON_YUV_IDLE wo
  [4] SL2_BUF_CONSM_SPARE_0_IDLE wo
  [3] SL2_BUF_NEIGHBORNEARFLAG_IDLE wo
  [2] SL2_BUF_SLICEINFO_IDLE wo
  [1] SL2_BUF_MBHDRINFO_BOT_IDLE wo
  [0] SL2_BUF_MBHDRINFO_TOP_IDLE wo
0x700 __ALL___DBG_CAP ro reset 0x500000 — This register contains the node revision code (all syncbox types) and all debug capacities of the module for HWa based syncbox only
  [26] DBG_SWBP_SUP — Whether HWA Core supports SWBP or not. b0 – Not Supported b1 – Supported
  [25] DBQ_RESET_SUP — Whether HWA Core reset is supported or not which does not affect debug logic. b0 – Not Supported b1 – Supported
  [24] SYS_EXE_REQ — Whether HWA Core Execution status and control is supported. b0 – Not Supported b1 – Supported
  [23] TRIG_OUTPUT — b0 – Trigger Outputs are not supported b1 - Trigger Outputs are supported
  [22] TRIG_INPUT — b0 - Trigger Inputs are not supported b1 - Trigger Inputs are supported
  [21:20] TRIG_CHNS — Number of Trigger Channels Supported b00 ------ No channels supported b01 ------ One channel supported b10 ------ Two channels supported Others ---- Reserved
  [19:16] NUM_CNTS — The number of counter modules that exist. The registers supporting the counter modules must be implemented consecutively in the memory map
  [15:12] NUM_WPS — The number of watchpoint modules that exist. The registers supporting the watchpoint modules must be implemented consecutively in the memory map
  [11:8] NUM_BPS — The number of breakpoint modules that exist. The registers supporting the breakpoint modules must be implemented consecutively in the memory map
0x704 __ALL___DBG_CNTL access per field
  [19:16] DBG_EMU0_CNTL ro — EMU0 output control. The cross trigger output control. This values in this field determine the behavior of the outputs generated on EMU0. NOTE: The effect of setting ‘1’ is ignored if the HWA Core is currently in HALTED state until the HWA core exits and re-enters HALTED state. DBG_EMUn_CNTL Output Enable Output Pulse Description 0 De-asserted 0 NA No output. Input only 1 Stopping 0 Yes Pulse on halt. If this bit is set when halted then no effect until the HWA re-enters halted state. 2 HWBP 0 Yes Pulse when any HWBP triggers 3 HWWP 0 Yes Pulse when any HWWP triggers 4 Asserted 1 No Drive pin high 5 Asserted 0 No Drive pin low 6-15 - - Reserved
  [14] DBG_STAT_EMU0 ro — Statues of EMU0 input. This bit indicates the current value of the EMU0 input
  [12] DBG_HALT_EMU0 ro — Execution halted due to trigger in on EMU0 input • Set to ‘1’ when halt due to EMU0 input completes • Set to ‘0’ when execution resumes
  [11] DBG_HALT_USER ro — Execution halted due to register update of DBG_HALT • Set to ‘1’ when halt due to DBG_HALT update completes • Set to ‘0’ when execution resumes
  [10] DBG_HALT_STEP ro — Execution halted due to single step completion • Set to ‘1’ when the single step completes • Set to ‘0’ when execution resumes
  [9] DBG_HALT_BPWP ro — Execution halted due to trigger from HWBP or WP. • Set to ‘1’ halt due to breakpoint or watchpoint completes • Set to ‘0’ when execution resumes
  [7] DBG_EXE_STAT ro — The execution status of the module • Set to ‘1’ when halted due to debug event • Set to ‘0’ when execution resumes
  [5] DBG_EMU0_EN rw — EMU0 input trigger enable • Writing ‘1’ enables halting on the falling edge of the EMU0 input • Writing ‘0’ disables halts via EMU0 input
  [4] DBG_WPBP_EN rw — This bit enables the halts on watchpoint or hardware breakpoint trigger events. • Writing ‘1’ enables halting on any hardware breakpoint or watchpoint trigger  Each breakpoint or watchpoint resource also has a local enable • Writing ‘0’ disables halts via hardware breakpoints or watchpoints
  [2] DBG_SINGLE_STEP_EN rw — Single Step Execution enable. When this bit is set, the accelerator core shall be halted upon execution of a single instruction. This is after the accelerator core has left the halted state by clearing the DBG_HALT control bit. • Writing ‘1’ enables halting when the next instruction following exit from halted state is executed. • Writing ‘0’ disables halts via single step. NOTE: 1. When the accelerator core enters its natural execution state, it may or may not execute an instruction and re-enter HALTED state.
  [1] DBG_RESTART rw — Debug Restart Status bit. This bit is normally set when the DBG_HALT bit transitions from ‘1’ to ‘0’ when the natural execution state is entered. It is a sticky bit. It may also be set when a synchronous run causes the accelerator to leave halted state. • Reading ‘1’ means HWA Core exited halted state (at least temporarily). • Reading ‘0’ means HWA Core did not exit halted state. • Writing ‘1’ shall clear the bit if set. There is no restriction on when it can be cleared. • Writing ‘0’ shall have no effect.
  [0] DBG_HALT rw — Global debug run control The bit will be read as being set upon entry to HALTED state due to halted state being entered because of SWBP, HWBP, HWWP, EMU0 / 1 trigger or manual halt requested through this control. • Writing ‘1’ when read ‘0’ shall cause a halt on the next possible halt boundary. • Writing ‘0’ when read ‘1’ returns the system to the natural execution state. A synchronous run hardware request has the same effect. • Reading ‘1’ means that the halted state has been reached or been requested by the manual halt mechanism • Reading ‘0’ means that the target is in its natural execution state. NOTE: 1. The natural execution state means the FSM state entered prior to last entry into Halted state. 2. This would be the last application requested FSM state unless the DBG_SYS_EXE_REQ control was used to change it.
0x708 __ALL___DBG_HWBP_0_CNTL access per field — Hardware Brakepoint-0 Control (at MB-Index) (LPF Execute Thread)
  [2] TRIGGERED rw — This bit is Set to "1" when HWBP located at the MB_Index in DBG_HWBP_n_MB_Index is executed Set to ‘1’ when executing the MB index = DBG_HWBP_n_MB_Index Cleared to ‘0’ by writing ‘1’ to this bit
  [1] HALT rw — This bit configures the module to generate halt when triggered Writing ‘1’ enables a HWA halt when triggered. The DBG_CNTL:DBG_HALT_BPWP must also be set for the halt to occur Writing ‘0’ disables halt upon trigger
  [0] ENBALE rw — This is the local enable for the hardware breakpoint module Writing ‘1’ to this bit enables the module to generate an instruction address match trigger Writing ‘0’ to this bit disables the module
0x70C __ALL___DBG_HWBP_0_MB_Index access per field — Hardware Brakepoint-0 : At MB-Index (LPF Execute Thread)
  [24:16] Column_Index rw, [8:0] Row_Index rw
0x710 __ALL___DBG_HWBP_1_CNTL access per field — Hardware Brakepoint-0 Control (at MB-Index) (LPF-vDMA Thread)
  fields as __ALL___DBG_HWBP_0_CNTL
0x714 __ALL___DBG_HWBP_1_MB_Index access per field — Hardware Brakepoint-0 : At MB-Index (LPF-vDMA Thread)
  [24:16] Column_Index rw, [8:0] Row_Index rw
0x730 __ALL___LF_DEBUG0 access per field
  [2] BYPASS_NF1_LOAD rw — Bypass NF1 loading from SL2 '1' = don't load NF1 from SL2, instead use programmed value '0' = NOrmal functional behavior
  [1] BYPASS_FILTER rw — Bypass Filter operation. CompBS, Loading of Param, Loading of Data and Storing of data happens as usual. ONLY filter engine is switched of.
  [0] BYPASS_CompBS rw — Bypass comp BS function
0x740 __ALL___DESIGN_RESERVED access per field — SW MUST Write 0 into all of its bits NO Coverage required for contents of this register. Primary usecase is to implement some controlled feature in future after MMR freeze.
  [n] FEATURE{n}_RESERVED rw (n=0..7)
0x780 __ALL___SL2_BUF_STATUS_MBHDRINFO_TOP ro reset 0x80000000 — Refer to SYNCBOX-5 functional specification
  [31] EMPTY, [27:26] READ_STATUS, [25:16] RD_POINTER, [15] full, [11:10] WR_STATUS, [9:0] WR_POINTER
0x784 __ALL___SL2_BUF_STATUS_MBHDRINFO_BOT ro reset 0x80000000 — Refer to SYNCBOX-5 functional specification
  fields as __ALL___SL2_BUF_STATUS_MBHDRINFO_TOP
0x788 __ALL___SL2_BUF_STATUS_SLICEINFO ro reset 0x80000000 — Refer to SYNCBOX-5 functional specification
  fields as __ALL___SL2_BUF_STATUS_MBHDRINFO_TOP
0x78C __ALL___SL2_BUF_STATUS_NEIGHBORNEARFLAG ro reset 0x80000000 — Refer to SYNCBOX-5 functional specification
  fields as __ALL___SL2_BUF_STATUS_MBHDRINFO_TOP
0x790 __ALL___SL2_BUF_STATUS_CONSM_SPARE_0 ro reset 0x80000000 — Refer to SYNCBOX-5 functional specification
  fields as __ALL___SL2_BUF_STATUS_MBHDRINFO_TOP
0x798 __ALL___LBC_BUF_STATUS_RECON_YUV ro reset 0x80000000 — Refer to SYNCBOX-5 functional specification
  fields as __ALL___SL2_BUF_STATUS_MBHDRINFO_TOP
0x79C __ALL___SL2_BUF_STATUS_VDMA_TRIGGER ro reset 0x80000000 — Refer to SYNCBOX-5 functional specification
  fields as __ALL___SL2_BUF_STATUS_MBHDRINFO_TOP
{0x800+4i} __ALL___LF_CUR_MB_INFO_{i} ro (i=0..3)
  [31:0] CUR_MB_INFO_{i} — CUR MBInfo[{32i+31}:{32i}]
{0x810+4i} __ALL___LF_SLICE_INFO_{i} ro (i=0..3)
  [31:0] SLICEINFO_WORD{i} — SliceInfo[{32i+31}:{32i}]
0x820 __ALL___LF_CUR_CBP ro — Calculated CBP for Current MB/MB-pair ( Using RSD_VALID from CALC ; details refer to LPF spec)
  [31:16] CBP_COMP_MB — CBP of complementry MB( MB-pair) [15:0]
  [15:0] CBP_CUR_MB — CBP[15:0]
0x824 __ALL___LF_MBAFF_COMP_MB_LF_PARAM ro — MBAFF Complimentary MB parameters. For current=TOP MB, this register is useless. For current=BOT MB of MBAFF, this register contains parameters of TOP MB of MBAFF-pair.
  [22:16] QP_CR
  [15:9] QP_CB
  [8:2] QP_Y — QP(Luma)
  [1] Frame_MB — Frame/Field MB for MBAFF.
  [0] INTRA
0x828 __ALL___LF_UPPER_TOP_LF_PARAM ro — Upper TOP MB Parameters (Only MBAFF)
  fields as __ALL___LF_MBAFF_COMP_MB_LF_PARAM
0x82C __ALL___LF_UPPER_BOT_LF_PARAM ro — Upper BOT MB Parameters (MBAFF) Upper MB for Non-MBAFF
  fields as __ALL___LF_MBAFF_COMP_MB_LF_PARAM
0x830 __ALL___LF_UPPER_CBP ro — Calculated CBP for Upper MB/MB-pair
  [23] UPPER_BOT_FRAMEPAIR_NEIGHBOR_CBP_3 — Neighbor Blockid[13] (Only MBAFF+Frame-pair)
  [22] UPPER_BOT_FRAMEPAIR_NEIGHBOR_CBP_2 — Neighbor Blockid[12] (Only MBAFF+Frame-pair)
  [21] UPPER_BOT_FRAMEPAIR_NEIGHBOR_CBP_1 — Neighbor Blockid[9] (Only MBAFF+Frame-pair)
  [20] UPPER_BOT_FRAMEPAIR_NEIGHBOR_CBP_0 — Neighbor Blockid[8] (Only MBAFF+Frame-pair)
  [19] UPPER_BOT_MB_NEIGHBOR_CBP_3 — Neighbor Blockid[15]
  [18] UPPER_BOT_MB_NEIGHBOR_CBP_2 — Neighbor Blockid[14]
  [17] UPPER_BOT_MB_NEIGHBOR_CBP_1 — Neighbor Blockid[11]
  [16] UPPER_BOT_MB_NEIGHBOR_CBP_0 — Neighbor Blockid[10]
  [3] UPPER_TOP_MB_NEIGHBOR_CBP_3 — Neighbor Blockid[15]
  [2] UPPER_TOP_MB_NEIGHBOR_CBP_2 — Neighbor Blockid[14]
  [1] UPPER_TOP_MB_NEIGHBOR_CBP_1 — Neighbor Blockid[11]
  [0] UPPER_TOP_MB_NEIGHBOR_CBP_0 — Neighbor Blockid[10]
0x83C __ALL___LF_NEIGHBOR_MB access per field — Neighbor MB number created during compBS to be used for averaging Qp values. neighbor_mb contains neibhbor MB number for All 8 pixels on Left MB Edge and one MB number for horizontal Mb Edge.
  [26:0] Neighbor_mb rw — [11:0] = MB_number for bs_edges [3,2,1,0] (Vertical MB edge) [23:12] = MB_number for bs_edges [35,34,33,32] (Vertical MB edge) [26:24] = MB_number for bs_edges [22] ( Horizontal MB edge)
0x840 __ALL___LF_NF — Neighbor Near Flag Value
  [31:0] NeighborNear_Flag — Neighbor Near flag bit0=edge0 bit31=edge31 as per NeighborNear Flag indexing as specified in spec. Value dumped by ECD5 into SL2 and loaded from SL2.
0x844 __ALL___LF_BS_0 access per field — Boundary Strength Value
  [3n+2:3n] BS_EDGE_{n} rw (n=0..9) — BS value
0x848 __ALL___LF_BS_1 access per field — Boundary Strength Value
  [3n-28:3n-30] BS_EDGE_{n} rw (n=11..19) — BS value
  [2:0] BS_EDGE_10 rw — BS value 1 msb of 3 bit of BS_EDGE_10
0x84C __ALL___LF_BS_2 access per field — Boundary Strength Value
  [3n-58:3n-60] BS_EDGE_{n} rw (n=22..29)
  [5:3] BS_EDGE_21 rw — BS value 2 msb of 3 bit of BS_EDGE_21
  [2:0] BS_EDGE_20 rw
0x850 __ALL___LF_BS_3 access per field — Boundary Strength Value for some extra edges in case of MBAFF MB boundary.
  [3n-88:3n-90] BS_EDGE_{n} rw (n=30..39) — BS value
0x854 __ALL___LF_STATUS_0 ro — All internal state machine status
  [31:0] LPF_INTERNAL_STATUS
0x858 __ALL___LF_VDMA_FILT_STATUS ro — filter buffer VDMA transfer status
  [5:2] TRIG_REGION — Triggered Region
  [1] VDMA_TRANSFER_STATUS
  [0] VDMA_TRIGGER_STATUS
0x85C __ALL___LF_VDMA_TOP_ROW_STATUS ro — top-row buffer VDMA transfer status
  fields as __ALL___LF_VDMA_FILT_STATUS
{0x860+4i} __ALL___HWA_THREAD_STATUS_{i} ro (i=0..2) — Thread[{i}] Status
  [6] HALT_DEBUG_OUT — Halted because of debug out request
  [5] HALT_DEBUG_IN — Halted because of pi_emu
  [4] HALT_REWIND — Halted because of rewind
  [3] HALT_PIPEDOWN — Thread piped down
  [2] HALT_INTR — Halted because of interrupt request
  [1] EXE — Execution state
  [0] WAIT — Waiting for the Tstart_req
0x86C __ALL___SCHEDULER_STATUS ro — Indicates HWA Status
  [2] PIPEDOWN — HWA is in pipedown
  [1] EXE — HWA is executing
  [0] INIT — HWA is autoloading/initializing
{0x900+0x10*i} LEFT_MEM_ENTRIES__{i}_LEFT_MEM_W_BUF_WORD0 (i=0..63) — 32b LSB of 128 bit word at one of Location[0:63] above pixels for one of 64 locations of Left Memory.Content of Each Location is described in Spec
  [31:0] bits_31_0
{0x904+0x10*i} LEFT_MEM_ENTRIES__{i}_LEFT_MEM_W_BUF_WORD1 (i=0..63) — 32b at bitposition [63:32] of 128 bit word at one of Location of Left Memory above pixels for one of 64 locations of Left Memory.Content of Each Location is described in Spec
  [31:0] bits_63_32
{0x908+0x10*i} LEFT_MEM_ENTRIES__{i}_LEFT_MEM_W_BUF_WORD2 (i=0..63) — 32b at bitposition [95:64] of 128 bit word at one of Location of Left Memory above pixels for one of 64 locations of Left Memory.Content of Each Location is described in Spec
  [31:0] bits_95_64
{0x90C+0x10*i} LEFT_MEM_ENTRIES__{i}_LEFT_MEM_W_BUF_WORD3 (i=0..63) — 32b at bitposition [127:96] of 128 bit word at one of Location of Left Memory above pixels for one of 64 locations of Left Memory.Content of Each Location is described in Spec
  [31:0] bits_127_96
{0x1100+0x10*i} LBC_MEM_ENTRIES__{i}_LBC_RECON_YUV_WORD0 (i=0..255) — Word0(32b) of LBC Memory location.( out of 4KB memory)
  [31:0] BITS_31_0
{0x1104+0x10*i} LBC_MEM_ENTRIES__{i}_LBC_RECON_YUV_WORD1 (i=0..255) — Word0(32b) of LBC Memory location.( out of 4KB memory)
  [31:0] BITS_63_32
{0x1108+0x10*i} LBC_MEM_ENTRIES__{i}_LBC_RECON_YUV_WORD2 (i=0..255) — Word0(32b) of LBC Memory location.( out of 4KB memory)
  [31:0] BITS_95_64
{0x110C+0x10*i} LBC_MEM_ENTRIES__{i}_LBC_RECON_YUV_WORD3 (i=0..255) — Word0(32b) of LBC Memory location.( out of 4KB memory)
  [31:0] BITS_127_96
